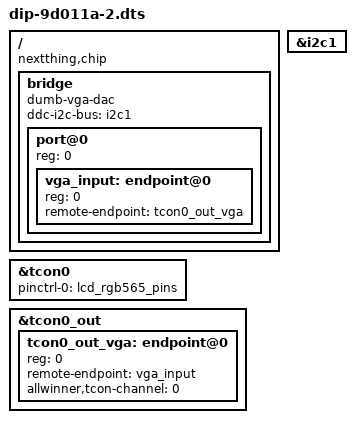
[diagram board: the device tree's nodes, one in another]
/dts-v1/;
/plugin/;

/ {
	compatible = "nextthing,chip", "allwinner,sun5i-r8", "allwinner,sun5i-a13";

	fragment@0{
		target-path = "/";

		__overlay__ {
			bridge {
				#address-cells = <1>;
				#size-cells = <0>;
				compatible = "dumb-vga-dac";
				ddc-i2c-bus = <&i2c1>;

				port@0 {
					reg = <0>;
					#address-cells = <1>;
					#size-cells = <0>;

					vga_input: endpoint@0 {
						reg = <0>;
						remote-endpoint = <&tcon0_out_vga>;
					};
				};
			};
		};
	};

	fragment@1{
		target = <&i2c1>;

		__overlay__ {
			status = "okay";
		};
	};

	fragment@2{
		target = <&tcon0>;

		__overlay__ {
			pinctrl-names = "default";
			pinctrl-0 = <&lcd_rgb565_pins>;
		};
	};

	fragment@3{
		target = <&tcon0_out>;

		__overlay__ {
			#address-cells = <1>;
			#size-cells = <0>;

			tcon0_out_vga: endpoint@0 {
				reg = <0>;
				remote-endpoint = <&vga_input>;
				allwinner,tcon-channel = <0>;
			};
		};
	};
};
